# MSS_RCM_MSS_RCM_53208000h register map
Vendor: Texas Instruments
Peripheral module from a debugger description file (folder AM263P).
Registers are 32-bit, read-write, reset 0x0 unless marked. A register's access mark holds for its fields unless they carry their own. Offsets are as the file gives them; lines under a group give offsets from that group; [hi:lo] are bit positions; {n}, {i} and the like mark numbered series; 'fields as' and 'values as' point back to an identical list; <NAME> marks a mode.

## MSS_RCM (part 1 of 2)
0x10 MSS_RCM_R5SS0_RST_STATUS ro reset 0x3 — R5SS Reset Cause Status register of corresponding R5SS.
  [10:0] R5SS0_RST_STATUS_CAUSE — Has the status because of which reset has happened. Bit0: POR ResetBit1: Warm Reset [ALso set during POR Reset]Bit2: CR5SS0 STC ResetBit3 Reset for CORE0 and MSS_CORE00_VIM using MSS_RCM::MSS_CR5SSA0_RST_CTRLBit4: Reset for CORE1 and MSS_CORE10_VIM using MSS_RCM::MSS_CR5SSB0_RST_CTRLBit5: Reset for CORE0 only using MSS_RCM::MSS_CORE00_RST_CTRLBit6: Reset for CORE1 only using using MSS_RCM::MSS_CORE10_RST_CTRLBit7: Reset for CORE0 and MSS_CORE00_VIM caused because of reset request by debugger in CORE00 Bit8: Reset for CORE10 and MSS_CORE10_VIM caused because of reset request by debugger in CORE10Bit9: Reset for CR5SS0 by the RESET FSM using MSS_CTRL::R5SS0_CONTROL_RESET_FSM_TRIGGER Bit10 : Reset for CR5SS0 using MSS_RCM.R5SS0_POR_RST_CTRL
0x14 MSS_RCM_R5SS0_RST_CAUSE_CLR — R5SS Reset Cause Clear register of corresponding R5SS.
  [2:0] R5SS0_RST_CAUSE_CLR_CLR — Write pulse bit field:Clear bit for rst cause register [Writing 3'b111 will clear the rst cause register]
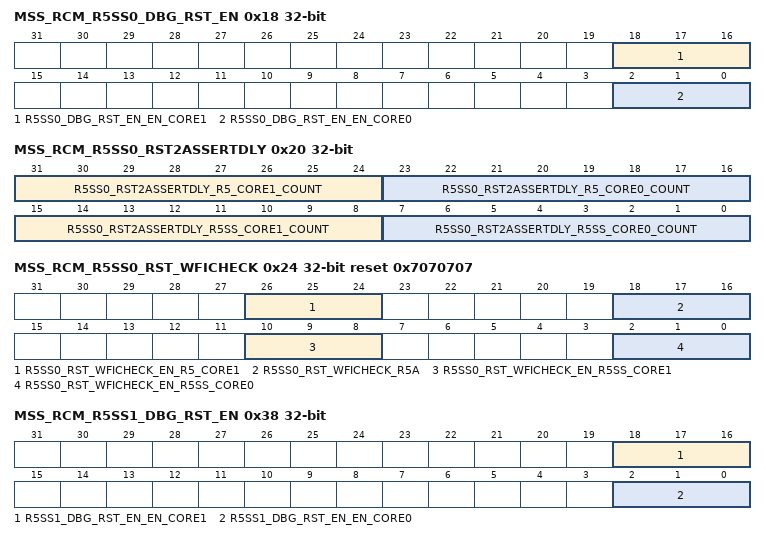
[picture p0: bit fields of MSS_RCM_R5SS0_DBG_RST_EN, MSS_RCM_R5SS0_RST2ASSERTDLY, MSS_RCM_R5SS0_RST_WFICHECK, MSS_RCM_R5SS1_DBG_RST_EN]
0x18 MSS_RCM_R5SS0_DBG_RST_EN — This register enables Core debug reset request to propogate to RCM.
  [18:16] R5SS0_DBG_RST_EN_EN_CORE1 — Writing 3'b111 will block debug reset request from CORE1 toggling reset for CORE1 of respective R5SS
  [2:0] R5SS0_DBG_RST_EN_EN_CORE0 — Writing 3'b111 will block debug reset request from CORE0 toggling reset for CORE0 of respective R5SS
0x1C MSS_RCM_R5SS0_RST_ASSERDLY reset 0xF — This register controls the reset duration of the corrseponding R5SS.
  [7:0] R5SS0_RST_ASSERDLY_COMMON — Value decides number of cycles reset should be kept asserted for CR5SS related resets. Programming a value of 0xFF will keep the reset asserted untill a new value other than 0xFF is written to this registerThe actual duration is count + 2 cycles. S/W Recommended value for this is 0x0FThe COUNT is applicable to both CPU cores
0x20 MSS_RCM_R5SS0_RST2ASSERTDLY — This register controls the delay of Reset assertion to the corresponding R5SS.
  [31:24] R5SS0_RST2ASSERTDLY_R5_CORE1_COUNT — Value decides number of cycles to wait before asserting reset for local reset for CORE1
  [23:16] R5SS0_RST2ASSERTDLY_R5_CORE0_COUNT — Value decides number of cycles to wait before asserting reset for local reset for CORE0.
  [15:8] R5SS0_RST2ASSERTDLY_R5SS_CORE1_COUNT — Value decides number of cycles to wait before asserting reset for global reset for CORE1
  [7:0] R5SS0_RST2ASSERTDLY_R5SS_CORE0_COUNT — Value decides number of cycles to wait before asserting reset for global reset for CORE0.
0x24 MSS_RCM_R5SS0_RST_WFICHECK reset 0x7070707 — Enable WFI ceck before R5 Reset is asserted.
  [26:24] R5SS0_RST_WFICHECK_EN_R5_CORE1 — Writing 3'b000 will disable check for WFI before local reset assertion of CORE0
  [18:16] R5SS0_RST_WFICHECK_R5A — Writing 3'b000 will disable check for WFI before local reset assertion of CORE0
  [10:8] R5SS0_RST_WFICHECK_EN_R5SS_CORE1 — Writing 3'b000 will disable check for WFI before global reset assertion of CORE1
  [2:0] R5SS0_RST_WFICHECK_EN_R5SS_CORE0 — Writing 3'b000 will disable check for WFI before global reset assertion of CORE0
0x30 MSS_RCM_R5SS1_RST_STATUS ro reset 0x3 — R5SS Reset Cause Status register of corresponding R5SS.
  [10:0] R5SS1_RST_STATUS_CAUSE — Has the status because of which reset has happened. Bit0: POR ResetBit1: Warm Reset [ALso set during POR Reset]Bit2: CR5SS1 STC ResetBit3 Reset for CORE0 and MSS_CORE00_VIM using MSS_RCM::MSS_CR5SSA0_RST_CTRLBit4: Reset for CORE1 and MSS_CORE10_VIM using MSS_RCM::MSS_CR5SSB0_RST_CTRLBit5: Reset for CORE0 only using MSS_RCM::MSS_CORE00_RST_CTRLBit6: Reset for CORE1 only using using MSS_RCM::MSS_CORE10_RST_CTRLBit7: Reset for CORE0 and MSS_CORE00_VIM caused because of reset request by debugger in CORE00 Bit8: Reset for CORE10 and MSS_CORE10_VIM caused because of reset request by debugger in CORE10Bit9: Reset for CR5SS0 by the RESET FSM using MSS_CTRL::R5SS0_CONTROL_RESET_FSM_TRIGGER Bit10 : Reset for CR5SS1 using MSS_RCM.R5SS0_POR_RST_CTRL
0x34 MSS_RCM_R5SS1_RST_CAUSE_CLR — R5SS Reset Cause Clear register of corresponding R5SS.
  [2:0] R5SS1_RST_CAUSE_CLR_CLR — Write pulse bit field:Clear bit for rst cause register [Writing 3'b111 will clear the rst cause register]
0x38 MSS_RCM_R5SS1_DBG_RST_EN — This register enables Core debug reset request to propogate to RCM.
  [18:16] R5SS1_DBG_RST_EN_EN_CORE1 — Writing 3'b111 will block debug reset request from CORE1 toggling reset for CORE1 of respective R5SS
  [2:0] R5SS1_DBG_RST_EN_EN_CORE0 — Writing 3'b111 will block debug reset request from CORE0 toggling reset for CORE0 of respective R5SS
0x3C MSS_RCM_R5SS1_RST_ASSERDLY reset 0xF — This register controls the reset duration of the corrseponding R5SS.
  [7:0] R5SS1_RST_ASSERDLY_COMMON — Value decides number of cycles reset should be kept asserted for CR5SS related resets. Programming a value of 0xFF will keep the reset asserted untill a new value other than 0xFF is written to this registerThe actual duration is count + 2 cycles. S/W Recommended value for this is 0x0FThe COUNT is applicable to both CPU cores
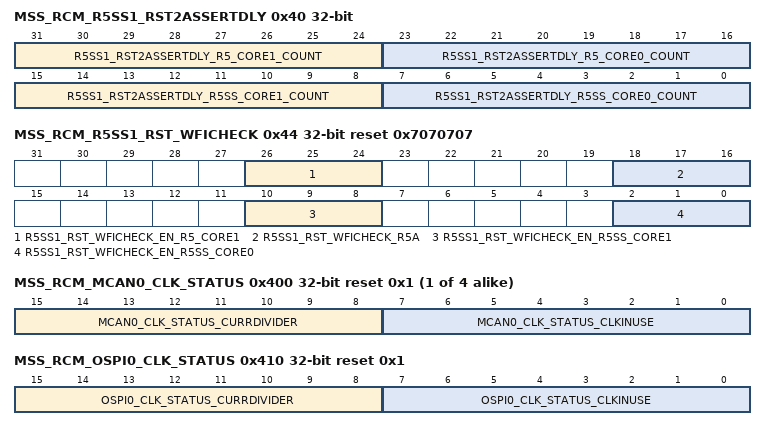
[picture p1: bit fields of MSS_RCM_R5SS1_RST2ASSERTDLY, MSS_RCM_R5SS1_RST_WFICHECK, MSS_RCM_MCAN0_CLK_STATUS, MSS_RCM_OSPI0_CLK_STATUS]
0x40 MSS_RCM_R5SS1_RST2ASSERTDLY — This register controls the delay of Reset assertion to the corresponding R5SS.
  [31:24] R5SS1_RST2ASSERTDLY_R5_CORE1_COUNT — Value decides number of cycles to wait before asserting reset for local reset for CORE1
  [23:16] R5SS1_RST2ASSERTDLY_R5_CORE0_COUNT — Value decides number of cycles to wait before asserting reset for local reset for CORE0.
  [15:8] R5SS1_RST2ASSERTDLY_R5SS_CORE1_COUNT — Value decides number of cycles to wait before asserting reset for global reset for CORE1
  [7:0] R5SS1_RST2ASSERTDLY_R5SS_CORE0_COUNT — Value decides number of cycles to wait before asserting reset for global reset for CORE0.
0x44 MSS_RCM_R5SS1_RST_WFICHECK reset 0x7070707 — Enable WFI ceck before R5 Reset is asserted.
  [26:24] R5SS1_RST_WFICHECK_EN_R5_CORE1 — Writing 3'b000 will disable check for WFI before local reset assertion of CORE0
  [18:16] R5SS1_RST_WFICHECK_R5A — Writing 3'b000 will disable check for WFI before local reset assertion of CORE0
  [10:8] R5SS1_RST_WFICHECK_EN_R5SS_CORE1 — Writing 3'b000 will disable check for WFI before global reset assertion of CORE1
  [2:0] R5SS1_RST_WFICHECK_EN_R5SS_CORE0 — Writing 3'b000 will disable check for WFI before global reset assertion of CORE0
0x80 MSS_RCM_CPSW_5_50_250_CLK_MUX_CTRL — CPSW CLK MUX CTRL to select DPLL_PER_HSDIV0_CLKOUT1 or DPLL_CORE_HSDIV0_CLKOUT1.
  [2:0] CPSW_5_50_250_CLK_MUX_CTRL_CLKSRCSEL — CPSW CLK MUX CTRL to select DPLL_PER_HSDIV0_CLKOUT1 or DPLL_CORE_HSDIV0_CLKOUT13'b000: DPLL_CORE_HSDIV0_CLKOUT1 [default]3'b111: DPLL_PER_HSDIV0_CLKOUT1**Note: The input clocks to the mux should be disabled when the mux select toggles.
{0x100+4i} MSS_RCM_MCAN{i}_CLK_SRC_SEL (i=0..3) — Clock Source selection Register for corresponding Root clock.
  [11:0] MCAN{i}_CLK_SRC_SEL_CLKSRCSEL — Select line for selecting source clock for corresponding MCAN.Data should be loaded as multibit. For example: if '0x5' should be selected then '0x555' should be configured to the register.Use the following values for selecting clock source-0x000 - WUCPUCLK0x111 - EXT_REFCLK0x222 - SYS_CLK0x333 - DPLL_PER_HSDIV0_CLKOUT10x444 - DPLL_CORE_HSDIV0_CLKOUT00x555 - RCCLK10M0x666 - XTALCLK0x777 - RCCLK10M
0x110 MSS_RCM_OSPI0_CLK_SRC_SEL — This Register is used for selecting the clock source for Corresponding root clock.
  [11:0] OSPI0_CLK_SRC_SEL_CLKSRCSEL — Select line for selecting source clock for OSPI.Data should be loaded as multibit. For example: if '0x5' should be selected then '0x555' should be configured to the register.Use the following values to select clk src-0x000 - WUCPUCLK0x111 - EXT_REFCLK0x222 - SYS_CLK0x333 - DPLL_PER_HSDIV0_CLKOUT10x444 - DPLL_CORE_HSDIV0_CLKOUT00x555 - RCCLK10M0x666 - DPLL_CORE_HSDIV0_CLKOUT30x777 - DPLL_PER_HSDIV0_CLKOUT2
{0x114+4i} MSS_RCM_RTI{i}_CLK_SRC_SEL (i=0..3) — This Register is used for selecting the clock source for Corresponding root clock.
  [11:0] RTI{i}_CLK_SRC_SEL_CLKSRCSEL — Select line for selecting source clock for Corresponding RTI.Data should be loaded as multibit. For example: if '0x5' should be selected then '0x555' should be configured to the register. Use the following values to select clk src- 0x000 - WUCPUCLK0x111 - EXT_REFCLK0x222 - SYS_CLK0x333 - DPLL_PER_HSDIV0_CLKOUT10x444 - DPLL_CORE_HSDIV0_CLKOUT00x555 - RCCLK10M0x666 - XTALCLK0x777 - CTPS_GENF0
{0x128+4i} MSS_RCM_WDT{i}_CLK_SRC_SEL (i=0..3) — This Register is used for selecting the clock source for Corresponding root clock.
  [11:0] WDT{i}_CLK_SRC_SEL_CLKSRCSEL — Select line for selecting source clock for WDT.Data should be loaded as multibit. For example: if '0x5' should be selected then '0x555' should be configured to the register.Use the following values to select clk src-0x000 - WUCPUCLK0x111 - RCCLK10M0x222 - SYS_CLK0x333 - DPLL_PER_HSDIV0_CLKOUT10x444 - DPLL_CORE_HSDIV0_CLKOUT00x555 - RCCLK10M0x666 - XTALCLK0x777 - RCCLK32K
{0x13C+4i} MSS_RCM_MCSPI{i}_CLK_SRC_SEL (i=0..4) — This Register is used for selecting the clock source for Corresponding root clock.
  [11:0] MCSPI{i}_CLK_SRC_SEL_CLKSRCSEL — Select line for selecting source clock for Corresponding SPI.Data should be loaded as multibit. For example: if '0x5' should be selected then '0x555' should be configured to the register.Use the following values to select clk src-0x000 - WUCPUCLK0x111 - EXT_REFCLK0x222 - SYS_CLK0x333 - DPLL_PER_HSDIV0_CLKOUT10x444 - DPLL_CORE_HSDIV0_CLKOUT00x555 - RCCLK10M0x666 - XTALCLK0x777 - RCCLK10M
0x150 MSS_RCM_MMC0_CLK_SRC_SEL — This Register is used for selecting the clock source for Corresponding root clock.
  [11:0] MMC0_CLK_SRC_SEL_CLKSRCSEL — Select line for selecting source clock for MMCSD.Data should be loaded as multibit. For example: if '0x5' should be selected then '0x555' should be configured to the register.Use the following values to select clk src-0x000 - WUCPUCLK0x111 - EXT_REFCLK0x222 - SYS_CLK0x333 - DPLL_PER_HSDIV0_CLKOUT10x444 - DPLL_CORE_HSDIV0_CLKOUT00x555 - RCCLK10M0x666 - XTALCLK0x777 - RCCLK10M
0x154 MSS_RCM_PRU_ICSS0_UART0_CLK_SRC_SEL — This Register is used for selecting the clock source for Corresponding root clock.
  [11:0] PRU_ICSS0_UART0_CLK_SRC_SEL_CLKSRCSEL — Select line for selecting source clock for ICSSM_UCLK.Data should be loaded as multibit. For example: if '0x5' should be selected then '0x555' should be configured to the register.Use the following values to select clk src-0x000 - WUCPUCLK0x111 - EXT_REFCLK0x222 - SYS_CLK0x333 - DPLL_PER_HSDIV0_CLKOUT10x444 - DPLL_CORE_HSDIV0_CLKOUT00x555 - RCCLK10M0x666 - XTALCLK0x777 - DPLL_PER_HSDIV0_CLKOUT0
0x158 MSS_RCM_CPTS_CLK_SRC_SEL — This Register is used for selecting the clock source for Corresponding root clock.
  [11:0] CPTS_CLK_SRC_SEL_CLKSRCSEL — Select line for selecting source clock for CPTS.Data should be loaded as multibit. For example: if '0x5' should be selected then '0x555' should be configured to the register.Use the following values to select clk src-0x000 - WUCPUCLK0x111 - EXT_REFCLK0x222 - SYS_CLK0x333 - DPLL_PER_HSDIV0_CLKOUT10x444 - DPLL_CORE_HSDIV0_CLKOUT00x555 - RCCLK10M0x666 - XTALCLK0x777 - RCCLK10M
0x160 MSS_RCM_CONTROLSS_PLL_CLK_SRC_SEL — This Register is used for selecting the clock source for Corresponding root clock.
  [11:0] CONTROLSS_PLL_CLK_SRC_SEL_CLKSRCSEL — Select line for selecting source clock for CONTROLSS_PLL.Data should be loaded as multibit. For example: if '0x5' should be selected then '0x555' should be configured to the register.Use the following values to select clk src-0x000 - WUCPUCLK0x111 - EXT_REFCLK0x222 - DPLL_CORE_HSDIV0_CLKOUT20x333 - DPLL_PER_HSDIV0_CLKOUT10x444 - DPLL_CORE_HSDIV0_CLKOUT00x555 - RCCLK10M0x666 - XTALCLK0x777 - RCCLK10M
0x164 MSS_RCM_I2C_CLK_SRC_SEL — This Register is used for selecting the clock source for Corresponding root clock.
  [11:0] I2C_CLK_SRC_SEL_CLKSRCSEL — Select line for selecting source clock for I2C.Data should be loaded as multibit. For example: if '0x5' should be selected then '0x555' should be configured to the register.Use the following values to select clk src-0x000 - WUCPUCLK0x111 - EXT_REFCLK0x222 - SYS_CLK0x333 - DPLL_PER_HSDIV0_CLKOUT10x444 - DPLL_CORE_HSDIV0_CLKOUT00x555 - RCCLK10M0x666 - XTALCLK0x777 - RCCLK10M
{0x174+4i} MSS_RCM_LIN{i}_UART{i}_CLK_SRC_SEL (i=0..5) — This Register is used for selecting the clock source for Corresponding root clock.
  [11:0] LIN{i}_UART{i}_CLK_SRC_SEL_CLKSRCSEL — Select line for selecting source clock for corresponding UART and LIN.Data should be loaded as multibit. For example: if '0x5' should be selected then '0x555' should be configured to the register.Use the following values to select clk src-0x000 - WUCPUCLK0x111 - EXT_REFCLK0x222 - SYS_CLK0x333 - DPLL_PER_HSDIV0_CLKOUT10x444 - DPLL_CORE_HSDIV0_CLKOUT00x555 - RCCLK10M0x666 - XTALCLK0x777 - DPLL_PER_HSDIV0_CLKOUT0
{0x17C+4i} MSS_RCM_MCAN{i}_CLK_SRC_SEL (i=4..7) — Clock Source selection Register for corresponding Root clock.
  fields as MSS_RCM_MCAN0_CLK_SRC_SEL
{0x18C+4i} MSS_RCM_RTI{i}_CLK_SRC_SEL (i=4..7) — This Register is used for selecting the clock source for Corresponding root clock.
  fields as MSS_RCM_RTI0_CLK_SRC_SEL
{0x198+4i} MSS_RCM_MCSPI{i}_CLK_SRC_SEL (i=5..7) — This Register is used for selecting the clock source for Corresponding root clock.
  fields as MSS_RCM_MCSPI0_CLK_SRC_SEL
{0x200+4i} MSS_RCM_MCAN{i}_CLK_DIV_VAL (i=0..3) — This Register is used to select the Divider value for respective clk.
  [11:0] MCAN{i}_CLK_DIV_VAL_CLKDIVR — Divider value corresponding MCAN selected clock.To set the divider value of [n+1] configure the register to value of '0xnnn'.Data should be loaded as multibit. For example: if divider value of '0x9' is required then '0x888' should be configured to the register.
0x210 MSS_RCM_OSPI0_CLK_DIV_VAL — This Register is used to select the Divider value for respective clk.
  [11:0] OSPI0_CLK_DIV_VAL_CLKDIVR — Divider value OSPI selected clock.To set the divider value of [n+1] configure the register to value of '0xnnn'.Data should be loaded as multibit. For example: if divider value of '0x9' is required then '0x888' should be configured to the register.
{0x214+4i} MSS_RCM_RTI{i}_CLK_DIV_VAL (i=0..3) — This Register is used to select the Divider value for respective clk.
  [11:0] RTI{i}_CLK_DIV_VAL_CLKDIVR — Divider value Corresponding RTI selected clock.To set the divider value of [n+1] configure the register to value of '0xnnn'.Data should be loaded as multibit. For example: if divider value of '0x9' is required then '0x888' should be configured to the register.
{0x228+4i} MSS_RCM_WDT{i}_CLK_DIV_VAL (i=0..3) — This Register is used to select the Divider value for respective clk.
  [11:0] WDT{i}_CLK_DIV_VAL_CLKDIVR — Divider value WDT selected clock.To set the divider value of [n+1] configure the register to value of '0xnnn'.Data should be loaded as multibit. For example: if divider value of '0x9' is required then '0x888' should be configured to the register.
{0x23C+4i} MSS_RCM_MCSPI{i}_CLK_DIV_VAL (i=0..4) — This Register is used to select the Divider value for respective clk.
  [11:0] MCSPI{i}_CLK_DIV_VAL_CLKDIVR — Divider value Corresponding SPI selected clock.To set the divider value of [n+1] configure the register to value of '0xnnn'.Data should be loaded as multibit. For example: if divider value of '0x9' is required then '0x888' should be configured to the register.
0x250 MSS_RCM_MMC0_CLK_DIV_VAL — This Register is used to select the Divider value for respective clk.
  [11:0] MMC0_CLK_DIV_VAL_CLKDIVR — Divider value MMCSD selected clock.To set the divider value of [n+1] configure the register to value of '0xnnn'.Data should be loaded as multibit. For example: if divider value of '0x9' is required then '0x888' should be configured to the register.
0x254 MSS_RCM_PRU_ICSS0_UART_CLK_DIV_VAL — This Register is used to select the Divider value for respective clk.
  [11:0] PRU_ICSS0_UART_CLK_DIV_VAL_CLKDIVR — Divider value ICSSM_UCLK selected clock.To set the divider value of [n+1] configure the register to value of '0xnnn'.Data should be loaded as multibit. For example: if divider value of '0x9' is required then '0x888' should be configured to the register.
0x258 MSS_RCM_CPTS_CLK_DIV_VAL — This Register is used to select the Divider value for respective clk.
  [11:0] CPTS_CLK_DIV_VAL_CLKDIVR — Divider value CPTS selected clock.To set the divider value of [n+1] configure the register to value of '0xnnn'.Data should be loaded as multibit. For example: if divider value of '0x9' is required then '0x888' should be configured to the register.
0x260 MSS_RCM_CONTROLSS_PLL_CLK_DIV_VAL — CONTROLSS_PLL_CLK Divider Value for Control subsystem.
  [11:0] CONTROLSS_PLL_CLK_DIV_VAL_CLKDIVR — Divider value CONTROLSS_PLL selected clock.To set the divider value of [n+1] configure the register to value of '0xnnn'.Data should be loaded as multibit. For example: if divider value of '0x9' is required then '0x888' should be configured to the register.
0x264 MSS_RCM_I2C_CLK_DIV_VAL — This Register is used to select the Divider value for respective clk.
  [11:0] I2C_CLK_DIV_VAL_CLKDIVR — Divider value I2C selected clock.To set the divider value of [n+1] configure the register to value of '0xnnn'.Data should be loaded as multibit. For example: if divider value of '0x9' is required then '0x888' should be configured to the register.
{0x274+4i} MSS_RCM_LIN{i}_UART{i}_CLK_DIV_VAL (i=0..5) — This Register is used to select the Divider value for respective clk.
  [11:0] LIN{i}_UART{i}_CLK_DIV_VAL_CLKDIVR — Divider value for corresponding UART and LIN selected clock.To set the divider value of [n+1] configure the register to value of '0xnnn'.Data should be loaded as multibit. For example: if divider value of '0x9' is required then '0x888' should be configured to the register.
0x28C MSS_RCM_RGMII_250_CLK_DIV_VAL reset 0x111 — RGMII 250 CLK Divider Value.
  [11:0] RGMII_250_CLK_DIV_VAL_CLKDIVR — Divider value RGMII selected clock.To set the divider value of [n+1] configure the register to value of '0xnnn'.Data should be loaded as multibit. For example: if divider value of '0x9' is required then '0x888' should be configured to the register.
0x290 MSS_RCM_RGMII_50_CLK_DIV_VAL reset 0x999 — RGMII 50 CLK Divider Value.
  [11:0] RGMII_50_CLK_DIV_VAL_CLKDIVR — Divider value MII100 selected clock.To set the divider value of [n+1] configure the register to value of '0xnnn'.Data should be loaded as multibit. For example: if divider value of '0x9' is required then '0x888' should be configured to the register.
0x294 MSS_RCM_RGMII_5_CLK_DIV_VAL reset 0x636363 — RGMII 5 CLK Divider Value.
  [23:0] RGMII_5_CLK_DIV_VAL_CLKDIVR — Divider value MII10 selected clock.To set the divider value of [n+1] configure the register to value of '0xnnn'.Data should be loaded as multibit. For example: if divider value of '0x15' is required then '0x151515' should be configured to the register.
0x298 MSS_RCM_XTAL_MMC_32K_CLK_DIV_VAL reset 0x30CC330C — XTAL 32K CLK Divider Value for MMC.
  [29:0] XTAL_MMC_32K_CLK_DIV_VAL_CLKDIVR — Divider value for XTAL_32K clock. To set the divider value of [n+1] configure the register to value of '0xnnn'.Data should be loaded as multibit. For example: if divider value of '0x30C' is required then register should be configured as follows -bits[9:0] = 0x30Cbits[19:10] = 0x30Cbits[29:20] = 0x30CThis configures the register to 0x30CC330C
0x29C MSS_RCM_XTAL_TEMPSENSE_32K_CLK_DIV_VAL reset 0x30CC330C — XTAL 32K CLK Divider Value for Temp Sensor.
  [29:0] XTAL_TEMPSENSE_32K_CLK_DIV_VAL_CLKDIVR — Divider value for XTAL_32K clock. To set the divider value of [n+1] configure the register to value of '0xnnn'.Data should be loaded as multibit. For example: if divider value of '0x30C' is required then register should be configured as follows -bits[9:0] = 0x30Cbits[19:10] = 0x30Cbits[29:20] = 0x30CThis configures the register to 0x30CC330C
{0x294+4i} MSS_RCM_MCAN{i}_CLK_DIV_VAL (i=4..7) — This Register is used to select the Divider value for respective clk.
  fields as MSS_RCM_MCAN0_CLK_DIV_VAL
{0x2A4+4i} MSS_RCM_RTI{i}_CLK_DIV_VAL (i=4..7) — This Register is used to select the Divider value for respective clk.
  fields as MSS_RCM_RTI0_CLK_DIV_VAL
{0x2B0+4i} MSS_RCM_MCSPI{i}_CLK_DIV_VAL (i=5..7) — This Register is used to select the Divider value for respective clk.
  fields as MSS_RCM_MCSPI0_CLK_DIV_VAL
{0x300+4i} MSS_RCM_MCAN{i}_CLK_GATE (i=0..3) — This Register is used to enable clk gating for the respective clk.
  [2:0] MCAN{i}_CLK_GATE_GATED — Writing 3'b111 will gate clock for corresponding MCAN
0x310 MSS_RCM_OSPI0_CLK_GATE — This Register is used to enable clk gating for the respective clk.
  [2:0] OSPI0_CLK_GATE_GATED — Writing 3'b111 will gate clock for OSPI
{0x314+4i} MSS_RCM_RTI{i}_CLK_GATE (i=0..3) — This Register is used to enable clk gating for the respective clk.
  [2:0] RTI{i}_CLK_GATE_GATED — Writing 3'b111 will gate clock for Corresponding RTI
{0x328+4i} MSS_RCM_WDT{i}_CLK_GATE (i=0..3) — This Register is used to enable clk gating for the respective clk.
  [2:0] WDT{i}_CLK_GATE_GATED — Writing 3'b111 will gate clock for WDT
{0x33C+4i} MSS_RCM_MCSPI{i}_CLK_GATE (i=0..4) — This Register is used to enable clk gating for the respective clk.
  [2:0] MCSPI{i}_CLK_GATE_GATED — Writing 3'b111 will gate clock for Corresponding SPI
0x350 MSS_RCM_MMC0_CLK_GATE — This Register is used to enable clk gating for the respective clk.
  [2:0] MMC0_CLK_GATE_GATED — Writing 3'b111 will gate clock for MMCSD
0x354 MSS_RCM_PRU_ICSS0_UART_CLK_GATE — This Register is used to enable clk gating for the respective clk.
  [2:0] PRU_ICSS0_UART_CLK_GATE_GATED — Writing 3'b111 will gate clock for ICSSM_UCLK
0x358 MSS_RCM_CPTS_CLK_GATE — This Register is used to enable clk gating for the respective clk.
  [2:0] CPTS_CLK_GATE_GATED — Writing 3'b111 will gate clock for CPTS
0x360 MSS_RCM_CONTROLSS_PLL_CLK_GATE — This Register is used to enable clk gating for the respective clk.
  [2:0] CONTROLSS_PLL_CLK_GATE_GATED — Writing 3'b111 will gate clock for CONTROLSS_PLL
{0x364+4i} MSS_RCM_I2C{i}_CLK_GATE (i=0..3) — This Register is used to enable clk gating for the respective clk.
  [2:0] I2C{i}_CLK_GATE_GATED — Writing 3'b111 will gate clock for I2C
{0x374+4i} MSS_RCM_LIN{i}_CLK_GATE (i=0..4) — This Register is used to enable clk gating for the respective clk.
  [2:0] LIN{i}_CLK_GATE_GATED — Writing 3'b111 will gate clock for SPIB
{0x38C+4i} MSS_RCM_UART{i}_CLK_GATE (i=0..5) — This Register is used to enable clk gating for the respective clk.
  [2:0] UART{i}_CLK_GATE_GATED — Writing 3'b111 will gate clock for corresponding UART
0x3A4 MSS_RCM_RGMII_250_CLK_GATE — This Register is used to enable clk gating for the respective clk.
  [2:0] RGMII_250_CLK_GATE_GATED — Writing 3'b111 will gate clock for RGMII
0x3A8 MSS_RCM_RGMII_50_CLK_GATE — This Register is used to enable clk gating for the respective clk.
  [2:0] RGMII_50_CLK_GATE_GATED — Writing 3'b111 will gate clock for MII100
0x3AC MSS_RCM_RGMII_5_CLK_GATE — This Register is used to enable clk gating for the respective clk.
  [2:0] RGMII_5_CLK_GATE_GATED — Writing 3'b111 will gate clock for MII10
0x3B0 MSS_RCM_MMC0_32K_CLK_GATE — This Register is used to enable clk gating for the respective clk.
  [2:0] MMC0_32K_CLK_GATE_GATED — Writing 3'b111 will gate clock for MMCSD_32K
0x3B4 MSS_RCM_TEMPSENSE_32K_CLK_GATE — This Register is used to enable clk gating for the respective clk.
  [2:0] TEMPSENSE_32K_CLK_GATE_GATED — Writing 3'b111 will gate clock for TEMPSENSE_32K
0x3B8 MSS_RCM_CPSW_CLK_GATE — This Register is used to enable clk gating for the respective clk.
  [2:0] CPSW_CLK_GATE_GATED — Writing 3'b111 will gate clock for CPSW CPPI
0x3BC MSS_RCM_PRU_ICSS0_IEP_CLK_GATE — This Register is used to enable clk gating for the respective clk.
  [2:0] PRU_ICSS0_IEP_CLK_GATE_GATED — Writing 3'b111 will gate clock for ICSSM_IEP
0x3C0 MSS_RCM_PRU_ICSS0_CORE_CLK_GATE — This Register is used to enable clk gating for the respective clk.
  [2:0] PRU_ICSS0_CORE_CLK_GATE_GATED — Writing 3'b111 will gate clock for ICSSM_CORE
0x3C4 MSS_RCM_MSS_PRU_ICSS_SYS_CLK_GATE — This Register is used to enable clk gating for the respective clk.
  [2:0] MSS_PRU_ICSS_SYS_CLK_GATE_GATED — Writing 3'b111 will gate clock for ICSSM_SYS
0x3CC MSS_RCM_R5SS0_CORE0_GATE — Clock gating for individual CPU core.
  [2:0] R5SS0_CORE0_GATE_CLKGATE — Writing 3'b111 will gate clock to CORE0 related peripherals inside Cortexr5ss
0x3D0 MSS_RCM_R5SS1_CORE0_GATE — Clock gating for individual CPU core.
  [2:0] R5SS1_CORE0_GATE_CLKGATE — Writing 3'b111 will gate clock to CORE0 related peripherals inside Cortexr5ss
0x3D4 MSS_RCM_R5SS0_CORE1_GATE — Clock gating for individual CPU core.
  [2:0] R5SS0_CORE1_GATE_CLKGATE — Writing 3'b111 will gate clock to CORE1 related peripherals inside Cortexr5ss
0x3D8 MSS_RCM_R5SS1_CORE1_GATE — Clock gating for individual CPU core.
  [2:0] R5SS1_CORE1_GATE_CLKGATE — Writing 3'b111 will gate clock to CORE1 related peripherals inside Cortexr5ss
{0x3CC+4i} MSS_RCM_MSS_MCAN{i}_CLK_GATE (i=4..7) — This Register is used to enable clk gating for the respective clk.
  [2:0] MSS_MCAN{i}_CLK_GATE_GATED — Writing 3'b111 will gate clock for corresponding MCAN
{0x3DC+4i} MSS_RCM_RTI{i}_CLK_GATE (i=4..7) — This Register is used to enable clk gating for the respective clk.
  fields as MSS_RCM_RTI0_CLK_GATE
{0x400+4i} MSS_RCM_MCAN{i}_CLK_STATUS ro reset 0x1 (i=0..3) — Clock source selection and Divider Value of respective clock.
  [15:8] MCAN{i}_CLK_STATUS_CURRDIVIDER — Status shows the current divider value choosen for corresponding MCAN
  [7:0] MCAN{i}_CLK_STATUS_CLKINUSE — Status shows the source clock slected for corresponding MCAN based on one hot encoding technique.
0x410 MSS_RCM_OSPI0_CLK_STATUS ro reset 0x1 — Clock source selection and Divider Value of respective clock.
  [15:8] OSPI0_CLK_STATUS_CURRDIVIDER — Status shows the current divider value choosen for OSPI
  [7:0] OSPI0_CLK_STATUS_CLKINUSE — Status shows the source clock slected for OSPI based on one hot encoding technique.
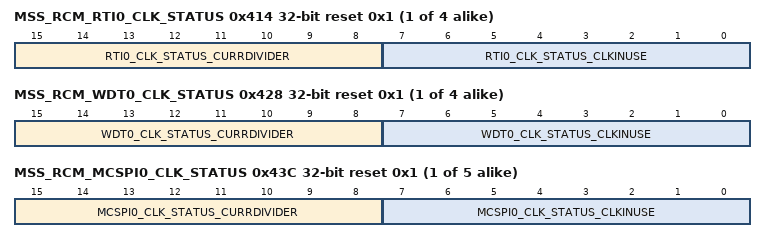
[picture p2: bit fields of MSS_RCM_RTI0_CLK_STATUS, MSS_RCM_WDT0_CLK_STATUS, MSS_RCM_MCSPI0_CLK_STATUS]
{0x414+4i} MSS_RCM_RTI{i}_CLK_STATUS ro reset 0x1 (i=0..3) — Clock source selection and Divider Value of respective clock.
  [15:8] RTI{i}_CLK_STATUS_CURRDIVIDER — Status shows the current divider value choosen for Corresponding RTI
  [7:0] RTI{i}_CLK_STATUS_CLKINUSE — Status shows the source clock slected for Corresponding RTI based on one hot encoding technique.
{0x428+4i} MSS_RCM_WDT{i}_CLK_STATUS ro reset 0x1 (i=0..3) — Clock source selection and Divider Value of respective clock.
  [15:8] WDT{i}_CLK_STATUS_CURRDIVIDER — Status shows the current divider value choosen for WDT
  [7:0] WDT{i}_CLK_STATUS_CLKINUSE — Status shows the source clock slected for WDT based on one hot encoding technique.
{0x43C+4i} MSS_RCM_MCSPI{i}_CLK_STATUS ro reset 0x1 (i=0..4) — Clock source selection and Divider Value of respective clock.
  [15:8] MCSPI{i}_CLK_STATUS_CURRDIVIDER — Status shows the current divider value choosen for Corresponding SPI
  [7:0] MCSPI{i}_CLK_STATUS_CLKINUSE — Status shows the source clock slected for Corresponding SPI based on one hot encoding technique.
